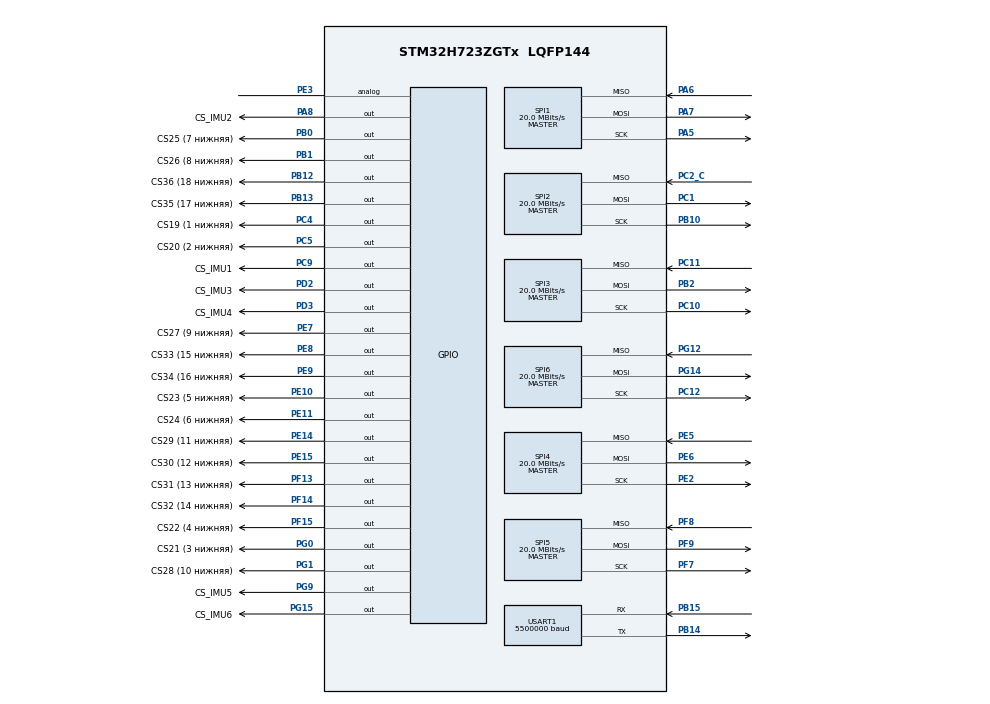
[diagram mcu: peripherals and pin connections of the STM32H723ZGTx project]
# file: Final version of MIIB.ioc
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Bdma.Request0=SPI6_RX
Bdma.Request1=SPI6_TX
Bdma.RequestsNb=2
Bdma.SPI6_RX.0.Direction=DMA_PERIPH_TO_MEMORY
Bdma.SPI6_RX.0.EventEnable=DISABLE
Bdma.SPI6_RX.0.Instance=BDMA_Channel0
Bdma.SPI6_RX.0.MemDataAlignment=DMA_MDATAALIGN_BYTE
Bdma.SPI6_RX.0.MemInc=DMA_MINC_ENABLE
Bdma.SPI6_RX.0.Mode=DMA_NORMAL
Bdma.SPI6_RX.0.PeriphDataAlignment=DMA_PDATAALIGN_BYTE
Bdma.SPI6_RX.0.PeriphInc=DMA_PINC_DISABLE
Bdma.SPI6_RX.0.Polarity=HAL_DMAMUX_REQ_GEN_RISING
Bdma.SPI6_RX.0.Priority=DMA_PRIORITY_VERY_HIGH
Bdma.SPI6_RX.0.RequestNumber=1
Bdma.SPI6_RX.0.SignalID=NONE
Bdma.SPI6_RX.0.SyncEnable=DISABLE
Bdma.SPI6_RX.0.SyncPolarity=HAL_DMAMUX_SYNC_NO_EVENT
Bdma.SPI6_RX.0.SyncRequestNumber=1
Bdma.SPI6_RX.0.SyncSignalID=NONE
Bdma.SPI6_TX.1.Direction=DMA_MEMORY_TO_PERIPH
Bdma.SPI6_TX.1.EventEnable=DISABLE
Bdma.SPI6_TX.1.Instance=BDMA_Channel1
Bdma.SPI6_TX.1.MemDataAlignment=DMA_MDATAALIGN_BYTE
Bdma.SPI6_TX.1.MemInc=DMA_MINC_ENABLE
Bdma.SPI6_TX.1.Mode=DMA_NORMAL
Bdma.SPI6_TX.1.PeriphDataAlignment=DMA_PDATAALIGN_BYTE
Bdma.SPI6_TX.1.PeriphInc=DMA_PINC_DISABLE
Bdma.SPI6_TX.1.Polarity=HAL_DMAMUX_REQ_GEN_RISING
Bdma.SPI6_TX.1.Priority=DMA_PRIORITY_HIGH
Bdma.SPI6_TX.1.RequestNumber=1
Bdma.SPI6_TX.1.SignalID=NONE
Bdma.SPI6_TX.1.SyncEnable=DISABLE
Bdma.SPI6_TX.1.SyncPolarity=HAL_DMAMUX_SYNC_NO_EVENT
Bdma.SPI6_TX.1.SyncRequestNumber=1
Bdma.SPI6_TX.1.SyncSignalID=NONE
CORTEX_M7.default_mode_Activation=1
Dma.Request0=USART1_RX
Dma.Request1=USART1_TX
Dma.Request10=SPI5_RX
Dma.Request11=SPI5_TX
Dma.Request2=SPI1_RX
Dma.Request3=SPI1_TX
Dma.Request4=SPI2_RX
Dma.Request5=SPI2_TX
Dma.Request6=SPI3_RX
Dma.Request7=SPI3_TX
Dma.Request8=SPI4_RX
Dma.Request9=SPI4_TX
Dma.SPI1_RX.2.Direction=DMA_PERIPH_TO_MEMORY
Dma.SPI1_RX.2.EventEnable=DISABLE
Dma.SPI1_RX.2.FIFOMode=DMA_FIFOMODE_DISABLE
Dma.SPI1_RX.2.Instance=DMA1_Stream2
Dma.SPI1_RX.2.MemDataAlignment=DMA_MDATAALIGN_BYTE
Dma.SPI1_RX.2.MemInc=DMA_MINC_ENABLE
Dma.SPI1_RX.2.Mode=DMA_NORMAL
Dma.SPI1_RX.2.PeriphDataAlignment=DMA_PDATAALIGN_BYTE
Dma.SPI1_RX.2.PeriphInc=DMA_PINC_DISABLE
Dma.SPI1_RX.2.Polarity=HAL_DMAMUX_REQ_GEN_RISING
Dma.SPI1_RX.2.Priority=DMA_PRIORITY_VERY_HIGH
Dma.SPI1_RX.2.RequestNumber=1
Dma.SPI1_RX.2.SignalID=NONE
Dma.SPI1_RX.2.SyncEnable=DISABLE
Dma.SPI1_RX.2.SyncPolarity=HAL_DMAMUX_SYNC_NO_EVENT
Dma.SPI1_RX.2.SyncRequestNumber=1
Dma.SPI1_RX.2.SyncSignalID=NONE
Dma.SPI1_TX.3.Direction=DMA_MEMORY_TO_PERIPH
Dma.SPI1_TX.3.EventEnable=DISABLE
Dma.SPI1_TX.3.FIFOMode=DMA_FIFOMODE_DISABLE
Dma.SPI1_TX.3.Instance=DMA1_Stream3
Dma.SPI1_TX.3.MemDataAlignment=DMA_MDATAALIGN_BYTE
Dma.SPI1_TX.3.MemInc=DMA_MINC_ENABLE
Dma.SPI1_TX.3.Mode=DMA_NORMAL
Dma.SPI1_TX.3.PeriphDataAlignment=DMA_PDATAALIGN_BYTE
Dma.SPI1_TX.3.PeriphInc=DMA_PINC_DISABLE
Dma.SPI1_TX.3.Polarity=HAL_DMAMUX_REQ_GEN_RISING
Dma.SPI1_TX.3.Priority=DMA_PRIORITY_HIGH
Dma.SPI1_TX.3.RequestNumber=1
Dma.SPI1_TX.3.SignalID=NONE
Dma.SPI1_TX.3.SyncEnable=DISABLE
Dma.SPI1_TX.3.SyncPolarity=HAL_DMAMUX_SYNC_NO_EVENT
Dma.SPI1_TX.3.SyncRequestNumber=1
Dma.SPI1_TX.3.SyncSignalID=NONE
Dma.SPI2_RX.4.Direction=DMA_PERIPH_TO_MEMORY
Dma.SPI2_RX.4.EventEnable=DISABLE
Dma.SPI2_RX.4.FIFOMode=DMA_FIFOMODE_DISABLE
Dma.SPI2_RX.4.Instance=DMA1_Stream4
Dma.SPI2_RX.4.MemDataAlignment=DMA_MDATAALIGN_BYTE
Dma.SPI2_RX.4.MemInc=DMA_MINC_ENABLE
Dma.SPI2_RX.4.Mode=DMA_NORMAL
Dma.SPI2_RX.4.PeriphDataAlignment=DMA_PDATAALIGN_BYTE
Dma.SPI2_RX.4.PeriphInc=DMA_PINC_DISABLE
Dma.SPI2_RX.4.Polarity=HAL_DMAMUX_REQ_GEN_RISING
Dma.SPI2_RX.4.Priority=DMA_PRIORITY_VERY_HIGH
Dma.SPI2_RX.4.RequestNumber=1
Dma.SPI2_RX.4.SignalID=NONE
Dma.SPI2_RX.4.SyncEnable=DISABLE
Dma.SPI2_RX.4.SyncPolarity=HAL_DMAMUX_SYNC_NO_EVENT
Dma.SPI2_RX.4.SyncRequestNumber=1
Dma.SPI2_RX.4.SyncSignalID=NONE
Dma.SPI2_TX.5.Direction=DMA_MEMORY_TO_PERIPH
Dma.SPI2_TX.5.EventEnable=DISABLE
Dma.SPI2_TX.5.FIFOMode=DMA_FIFOMODE_DISABLE
Dma.SPI2_TX.5.Instance=DMA1_Stream5
Dma.SPI2_TX.5.MemDataAlignment=DMA_MDATAALIGN_BYTE
Dma.SPI2_TX.5.MemInc=DMA_MINC_ENABLE
Dma.SPI2_TX.5.Mode=DMA_NORMAL
Dma.SPI2_TX.5.PeriphDataAlignment=DMA_PDATAALIGN_BYTE
Dma.SPI2_TX.5.PeriphInc=DMA_PINC_DISABLE
Dma.SPI2_TX.5.Polarity=HAL_DMAMUX_REQ_GEN_RISING
Dma.SPI2_TX.5.Priority=DMA_PRIORITY_HIGH
Dma.SPI2_TX.5.RequestNumber=1
Dma.SPI2_TX.5.SignalID=NONE
Dma.SPI2_TX.5.SyncEnable=DISABLE
Dma.SPI2_TX.5.SyncPolarity=HAL_DMAMUX_SYNC_NO_EVENT
Dma.SPI2_TX.5.SyncRequestNumber=1
Dma.SPI2_TX.5.SyncSignalID=NONE
Dma.SPI3_RX.6.Direction=DMA_PERIPH_TO_MEMORY
Dma.SPI3_RX.6.EventEnable=DISABLE
Dma.SPI3_RX.6.FIFOMode=DMA_FIFOMODE_DISABLE
Dma.SPI3_RX.6.Instance=DMA1_Stream6
Dma.SPI3_RX.6.MemDataAlignment=DMA_MDATAALIGN_BYTE
Dma.SPI3_RX.6.MemInc=DMA_MINC_ENABLE
Dma.SPI3_RX.6.Mode=DMA_NORMAL
Dma.SPI3_RX.6.PeriphDataAlignment=DMA_PDATAALIGN_BYTE
Dma.SPI3_RX.6.PeriphInc=DMA_PINC_DISABLE
Dma.SPI3_RX.6.Polarity=HAL_DMAMUX_REQ_GEN_RISING
Dma.SPI3_RX.6.Priority=DMA_PRIORITY_VERY_HIGH
Dma.SPI3_RX.6.RequestNumber=1
Dma.SPI3_RX.6.SignalID=NONE
Dma.SPI3_RX.6.SyncEnable=DISABLE
Dma.SPI3_RX.6.SyncPolarity=HAL_DMAMUX_SYNC_NO_EVENT
Dma.SPI3_RX.6.SyncRequestNumber=1
Dma.SPI3_RX.6.SyncSignalID=NONE
Dma.SPI3_TX.7.Direction=DMA_MEMORY_TO_PERIPH
Dma.SPI3_TX.7.EventEnable=DISABLE
Dma.SPI3_TX.7.FIFOMode=DMA_FIFOMODE_DISABLE
Dma.SPI3_TX.7.Instance=DMA1_Stream7
Dma.SPI3_TX.7.MemDataAlignment=DMA_MDATAALIGN_BYTE
Dma.SPI3_TX.7.MemInc=DMA_MINC_ENABLE
Dma.SPI3_TX.7.Mode=DMA_NORMAL
Dma.SPI3_TX.7.PeriphDataAlignment=DMA_PDATAALIGN_BYTE
Dma.SPI3_TX.7.PeriphInc=DMA_PINC_DISABLE
Dma.SPI3_TX.7.Polarity=HAL_DMAMUX_REQ_GEN_RISING
Dma.SPI3_TX.7.Priority=DMA_PRIORITY_HIGH
Dma.SPI3_TX.7.RequestNumber=1
Dma.SPI3_TX.7.SignalID=NONE
Dma.SPI3_TX.7.SyncEnable=DISABLE
Dma.SPI3_TX.7.SyncPolarity=HAL_DMAMUX_SYNC_NO_EVENT
Dma.SPI3_TX.7.SyncRequestNumber=1
Dma.SPI3_TX.7.SyncSignalID=NONE
Dma.SPI4_RX.8.Direction=DMA_PERIPH_TO_MEMORY
Dma.SPI4_RX.8.EventEnable=DISABLE
Dma.SPI4_RX.8.FIFOMode=DMA_FIFOMODE_DISABLE
Dma.SPI4_RX.8.Instance=DMA2_Stream0
Dma.SPI4_RX.8.MemDataAlignment=DMA_MDATAALIGN_BYTE
Dma.SPI4_RX.8.MemInc=DMA_MINC_ENABLE
Dma.SPI4_RX.8.Mode=DMA_NORMAL
Dma.SPI4_RX.8.PeriphDataAlignment=DMA_PDATAALIGN_BYTE
Dma.SPI4_RX.8.PeriphInc=DMA_PINC_DISABLE
Dma.SPI4_RX.8.Polarity=HAL_DMAMUX_REQ_GEN_RISING
Dma.SPI4_RX.8.Priority=DMA_PRIORITY_VERY_HIGH
Dma.SPI4_RX.8.RequestNumber=1
Dma.SPI4_RX.8.SignalID=NONE
Dma.SPI4_RX.8.SyncEnable=DISABLE
Dma.SPI4_RX.8.SyncPolarity=HAL_DMAMUX_SYNC_NO_EVENT
Dma.SPI4_RX.8.SyncRequestNumber=1
Dma.SPI4_RX.8.SyncSignalID=NONE
Dma.SPI4_TX.9.Direction=DMA_MEMORY_TO_PERIPH
Dma.SPI4_TX.9.EventEnable=DISABLE
Dma.SPI4_TX.9.FIFOMode=DMA_FIFOMODE_DISABLE
Dma.SPI4_TX.9.Instance=DMA2_Stream1
Dma.SPI4_TX.9.MemDataAlignment=DMA_MDATAALIGN_BYTE
Dma.SPI4_TX.9.MemInc=DMA_MINC_ENABLE
Dma.SPI4_TX.9.Mode=DMA_NORMAL
Dma.SPI4_TX.9.PeriphDataAlignment=DMA_PDATAALIGN_BYTE
Dma.SPI4_TX.9.PeriphInc=DMA_PINC_DISABLE
Dma.SPI4_TX.9.Polarity=HAL_DMAMUX_REQ_GEN_RISING
Dma.SPI4_TX.9.Priority=DMA_PRIORITY_HIGH
Dma.SPI4_TX.9.RequestNumber=1
Dma.SPI4_TX.9.SignalID=NONE
Dma.SPI4_TX.9.SyncEnable=DISABLE
Dma.SPI4_TX.9.SyncPolarity=HAL_DMAMUX_SYNC_NO_EVENT
Dma.SPI4_TX.9.SyncRequestNumber=1
Dma.SPI4_TX.9.SyncSignalID=NONE
Dma.SPI5_RX.10.Direction=DMA_PERIPH_TO_MEMORY
Dma.SPI5_RX.10.EventEnable=DISABLE
Dma.SPI5_RX.10.FIFOMode=DMA_FIFOMODE_DISABLE
Dma.SPI5_RX.10.Instance=DMA2_Stream2
Dma.SPI5_RX.10.MemDataAlignment=DMA_MDATAALIGN_BYTE
Dma.SPI5_RX.10.MemInc=DMA_MINC_ENABLE
Dma.SPI5_RX.10.Mode=DMA_NORMAL
Dma.SPI5_RX.10.PeriphDataAlignment=DMA_PDATAALIGN_BYTE
Dma.SPI5_RX.10.PeriphInc=DMA_PINC_DISABLE
Dma.SPI5_RX.10.Polarity=HAL_DMAMUX_REQ_GEN_RISING
Dma.SPI5_RX.10.Priority=DMA_PRIORITY_VERY_HIGH
Dma.SPI5_RX.10.RequestNumber=1
Dma.SPI5_RX.10.SignalID=NONE
Dma.SPI5_RX.10.SyncEnable=DISABLE
Dma.SPI5_RX.10.SyncPolarity=HAL_DMAMUX_SYNC_NO_EVENT
Dma.SPI5_RX.10.SyncRequestNumber=1
Dma.SPI5_RX.10.SyncSignalID=NONE
Dma.SPI5_TX.11.Direction=DMA_MEMORY_TO_PERIPH
Dma.SPI5_TX.11.EventEnable=DISABLE
Dma.SPI5_TX.11.FIFOMode=DMA_FIFOMODE_DISABLE
Dma.SPI5_TX.11.Instance=DMA2_Stream3
Dma.SPI5_TX.11.MemDataAlignment=DMA_MDATAALIGN_BYTE
Dma.SPI5_TX.11.MemInc=DMA_MINC_ENABLE
Dma.SPI5_TX.11.Mode=DMA_NORMAL
Dma.SPI5_TX.11.PeriphDataAlignment=DMA_PDATAALIGN_BYTE
Dma.SPI5_TX.11.PeriphInc=DMA_PINC_DISABLE
Dma.SPI5_TX.11.Polarity=HAL_DMAMUX_REQ_GEN_RISING
Dma.SPI5_TX.11.Priority=DMA_PRIORITY_HIGH
Dma.SPI5_TX.11.RequestNumber=1
Dma.SPI5_TX.11.SignalID=NONE
Dma.SPI5_TX.11.SyncEnable=DISABLE
Dma.SPI5_TX.11.SyncPolarity=HAL_DMAMUX_SYNC_NO_EVENT
Dma.SPI5_TX.11.SyncRequestNumber=1
Dma.SPI5_TX.11.SyncSignalID=NONE
Dma.USART1_RX.0.Direction=DMA_PERIPH_TO_MEMORY
Dma.USART1_RX.0.EventEnable=DISABLE
Dma.USART1_RX.0.FIFOMode=DMA_FIFOMODE_DISABLE
Dma.USART1_RX.0.Instance=DMA1_Stream0
Dma.USART1_RX.0.MemDataAlignment=DMA_MDATAALIGN_BYTE
Dma.USART1_RX.0.MemInc=DMA_MINC_ENABLE
Dma.USART1_RX.0.Mode=DMA_NORMAL
Dma.USART1_RX.0.PeriphDataAlignment=DMA_PDATAALIGN_BYTE
Dma.USART1_RX.0.PeriphInc=DMA_PINC_DISABLE
Dma.USART1_RX.0.Polarity=HAL_DMAMUX_REQ_GEN_RISING
Dma.USART1_RX.0.Priority=DMA_PRIORITY_HIGH
Dma.USART1_RX.0.RequestNumber=1
Dma.USART1_RX.0.SignalID=NONE
Dma.USART1_RX.0.SyncEnable=DISABLE
Dma.USART1_RX.0.SyncPolarity=HAL_DMAMUX_SYNC_NO_EVENT
Dma.USART1_RX.0.SyncRequestNumber=1
Dma.USART1_RX.0.SyncSignalID=NONE
Dma.USART1_TX.1.Direction=DMA_MEMORY_TO_PERIPH
Dma.USART1_TX.1.EventEnable=DISABLE
Dma.USART1_TX.1.FIFOMode=DMA_FIFOMODE_DISABLE
Dma.USART1_TX.1.Instance=DMA1_Stream1
Dma.USART1_TX.1.MemDataAlignment=DMA_MDATAALIGN_BYTE
Dma.USART1_TX.1.MemInc=DMA_MINC_ENABLE
Dma.USART1_TX.1.Mode=DMA_NORMAL
Dma.USART1_TX.1.PeriphDataAlignment=DMA_PDATAALIGN_BYTE
Dma.USART1_TX.1.PeriphInc=DMA_PINC_DISABLE
Dma.USART1_TX.1.Polarity=HAL_DMAMUX_REQ_GEN_RISING
Dma.USART1_TX.1.Priority=DMA_PRIORITY_MEDIUM
Dma.USART1_TX.1.RequestNumber=1
Dma.USART1_TX.1.SignalID=NONE
Dma.USART1_TX.1.SyncEnable=DISABLE
Dma.USART1_TX.1.SyncPolarity=HAL_DMAMUX_SYNC_NO_EVENT
Dma.USART1_TX.1.SyncRequestNumber=1
Dma.USART1_TX.1.SyncSignalID=NONE
Mcu.Family=STM32H7
Mcu.Name=STM32H723ZGTx
Mcu.Package=LQFP144
NVIC.BDMA_Channel0_IRQn=true\:0\:0\:false\:false\:true\:false\:true\:true
NVIC.BDMA_Channel1_IRQn=true\:0\:0\:false\:false\:true\:false\:true\:true
NVIC.DMA1_Stream0_IRQn=true\:0\:0\:false\:false\:true\:false\:true\:true
NVIC.DMA1_Stream1_IRQn=true\:0\:0\:false\:false\:true\:false\:true\:true
NVIC.DMA1_Stream2_IRQn=true\:0\:0\:false\:false\:true\:false\:true\:true
NVIC.DMA1_Stream3_IRQn=true\:0\:0\:false\:false\:true\:false\:true\:true
NVIC.DMA1_Stream4_IRQn=true\:0\:0\:false\:false\:true\:false\:true\:true
NVIC.DMA1_Stream5_IRQn=true\:0\:0\:false\:false\:true\:false\:true\:true
NVIC.DMA1_Stream6_IRQn=true\:0\:0\:false\:false\:true\:false\:true\:true
NVIC.DMA1_Stream7_IRQn=true\:0\:0\:false\:false\:true\:false\:true\:true
NVIC.DMA2_Stream0_IRQn=true\:0\:0\:false\:false\:true\:false\:true\:true
NVIC.DMA2_Stream1_IRQn=true\:0\:0\:false\:false\:true\:false\:true\:true
NVIC.DMA2_Stream2_IRQn=true\:0\:0\:false\:false\:true\:false\:true\:true
NVIC.DMA2_Stream3_IRQn=true\:0\:0\:false\:false\:true\:false\:true\:true
NVIC.PriorityGroup=NVIC_PRIORITYGROUP_4
NVIC.SPI1_IRQn=true\:0\:0\:false\:false\:true\:false\:true\:true
NVIC.SPI2_IRQn=true\:0\:0\:false\:false\:true\:false\:true\:true
NVIC.SPI3_IRQn=true\:0\:0\:false\:false\:true\:false\:true\:true
NVIC.SPI4_IRQn=true\:0\:0\:false\:false\:true\:false\:true\:true
NVIC.SPI5_IRQn=true\:0\:0\:false\:false\:true\:false\:true\:true
NVIC.SPI6_IRQn=true\:0\:0\:false\:false\:true\:false\:true\:true
NVIC.TIM6_DAC_IRQn=true\:0\:0\:true\:false\:true\:true\:true\:true
PA13(JTMS/SWDIO).Mode=Serial_Wire
PA13(JTMS/SWDIO).Signal=DEBUG_JTMS-SWDIO
PA14(JTCK/SWCLK).Mode=Serial_Wire
PA14(JTCK/SWCLK).Signal=DEBUG_JTCK-SWCLK
PA5.GPIO_Speed=GPIO_SPEED_FREQ_VERY_HIGH
PA5.Mode=Full_Duplex_Master
PA5.Signal=SPI1_SCK
PA6.GPIO_Speed=GPIO_SPEED_FREQ_VERY_HIGH
PA6.Mode=Full_Duplex_Master
PA6.Signal=SPI1_MISO
PA7.GPIO_Speed=GPIO_SPEED_FREQ_VERY_HIGH
PA7.Mode=Full_Duplex_Master
PA7.Signal=SPI1_MOSI
PA8.GPIO_Label=CS_IMU2
PA8.GPIO_Speed=GPIO_SPEED_FREQ_VERY_HIGH
PA8.PinState=GPIO_PIN_SET
PA8.Signal=GPIO_Output
PB0.GPIO_Label=CS25 (7 \u043D\u0438\u0436\u043D\u044F\u044F)
PB0.GPIO_Speed=GPIO_SPEED_FREQ_HIGH
PB0.Signal=GPIO_Output
PB1.GPIO_Label=CS26 (8 \u043D\u0438\u0436\u043D\u044F\u044F)
PB1.GPIO_Speed=GPIO_SPEED_FREQ_HIGH
PB1.Signal=GPIO_Output
PB10.GPIO_Speed=GPIO_SPEED_FREQ_VERY_HIGH
PB10.Mode=Full_Duplex_Master
PB10.Signal=SPI2_SCK
PB12.GPIO_Label=CS36 (18 \u043D\u0438\u0436\u043D\u044F\u044F)
PB12.GPIO_Speed=GPIO_SPEED_FREQ_HIGH
PB12.Signal=GPIO_Output
PB13.GPIO_Label=CS35 (17 \u043D\u0438\u0436\u043D\u044F\u044F)
PB13.GPIO_Speed=GPIO_SPEED_FREQ_HIGH
PB13.Signal=GPIO_Output
PB14.GPIO_Speed=GPIO_SPEED_FREQ_VERY_HIGH
PB14.Mode=Asynchronous
PB14.Signal=USART1_TX
PB15.GPIO_Speed=GPIO_SPEED_FREQ_VERY_HIGH
PB15.Mode=Asynchronous
PB15.Signal=USART1_RX
PB2.GPIO_Speed=GPIO_SPEED_FREQ_VERY_HIGH
PB2.Mode=Full_Duplex_Master
PB2.Signal=SPI3_MOSI
PC1.GPIO_Speed=GPIO_SPEED_FREQ_VERY_HIGH
PC1.Mode=Full_Duplex_Master
PC1.Signal=SPI2_MOSI
PC10.GPIO_Speed=GPIO_SPEED_FREQ_VERY_HIGH
PC10.Mode=Full_Duplex_Master
PC10.Signal=SPI3_SCK
PC11.GPIO_Speed=GPIO_SPEED_FREQ_VERY_HIGH
PC11.Mode=Full_Duplex_Master
PC11.Signal=SPI3_MISO
PC12.GPIO_Speed=GPIO_SPEED_FREQ_VERY_HIGH
PC12.Mode=Full_Duplex_Master
PC12.Signal=SPI6_SCK
PC2_C.GPIO_Speed=GPIO_SPEED_FREQ_VERY_HIGH
PC2_C.Mode=Full_Duplex_Master
PC2_C.Signal=SPI2_MISO
PC4.GPIO_Label=CS19 (1 \u043D\u0438\u0436\u043D\u044F\u044F)
PC4.GPIO_Speed=GPIO_SPEED_FREQ_HIGH
PC4.Signal=GPIO_Output
PC5.GPIO_Label=CS20 (2 \u043D\u0438\u0436\u043D\u044F\u044F)
PC5.GPIO_Speed=GPIO_SPEED_FREQ_HIGH
PC5.Signal=GPIO_Output
PC9.GPIO_Label=CS_IMU1
PC9.GPIO_Speed=GPIO_SPEED_FREQ_VERY_HIGH
PC9.PinState=GPIO_PIN_SET
PC9.Signal=GPIO_Output
PD2.GPIO_Label=CS_IMU3
PD2.GPIO_Speed=GPIO_SPEED_FREQ_VERY_HIGH
PD2.PinState=GPIO_PIN_SET
PD2.Signal=GPIO_Output
PD3.GPIO_Label=CS_IMU4
PD3.GPIO_Speed=GPIO_SPEED_FREQ_VERY_HIGH
PD3.PinState=GPIO_PIN_SET
PD3.Signal=GPIO_Output
PE10.GPIO_Label=CS23 (5 \u043D\u0438\u0436\u043D\u044F\u044F)
PE10.GPIO_Speed=GPIO_SPEED_FREQ_HIGH
PE10.Signal=GPIO_Output
PE11.GPIO_Label=CS24 (6 \u043D\u0438\u0436\u043D\u044F\u044F)
PE11.GPIO_Speed=GPIO_SPEED_FREQ_HIGH
PE11.Signal=GPIO_Output
PE14.GPIO_Label=CS29 (11 \u043D\u0438\u0436\u043D\u044F\u044F)
PE14.GPIO_Speed=GPIO_SPEED_FREQ_HIGH
PE14.Signal=GPIO_Output
PE15.GPIO_Label=CS30 (12 \u043D\u0438\u0436\u043D\u044F\u044F)
PE15.GPIO_Speed=GPIO_SPEED_FREQ_HIGH
PE15.Signal=GPIO_Output
PE2.GPIO_Speed=GPIO_SPEED_FREQ_VERY_HIGH
PE2.Mode=Full_Duplex_Master
PE2.Signal=SPI4_SCK
PE3.Signal=GPIO_Analog
PE5.GPIO_Speed=GPIO_SPEED_FREQ_VERY_HIGH
PE5.Mode=Full_Duplex_Master
PE5.Signal=SPI4_MISO
PE6.GPIO_Speed=GPIO_SPEED_FREQ_VERY_HIGH
PE6.Mode=Full_Duplex_Master
PE6.Signal=SPI4_MOSI
PE7.GPIO_Label=CS27 (9 \u043D\u0438\u0436\u043D\u044F\u044F)
PE7.GPIO_Speed=GPIO_SPEED_FREQ_HIGH
PE7.Signal=GPIO_Output
PE8.GPIO_Label=CS33 (15 \u043D\u0438\u0436\u043D\u044F\u044F)
PE8.GPIO_Speed=GPIO_SPEED_FREQ_HIGH
PE8.Signal=GPIO_Output
PE9.GPIO_Label=CS34 (16 \u043D\u0438\u0436\u043D\u044F\u044F)
PE9.GPIO_Speed=GPIO_SPEED_FREQ_HIGH
PE9.Signal=GPIO_Output
PF13.GPIO_Label=CS31 (13 \u043D\u0438\u0436\u043D\u044F\u044F)
PF13.GPIO_Speed=GPIO_SPEED_FREQ_HIGH
PF13.Signal=GPIO_Output
PF14.GPIO_Label=CS32 (14 \u043D\u0438\u0436\u043D\u044F\u044F)
PF14.GPIO_Speed=GPIO_SPEED_FREQ_HIGH
PF14.Signal=GPIO_Output
PF15.GPIO_Label=CS22 (4 \u043D\u0438\u0436\u043D\u044F\u044F)
PF15.GPIO_Speed=GPIO_SPEED_FREQ_HIGH
PF15.Signal=GPIO_Output
PF7.GPIO_Speed=GPIO_SPEED_FREQ_VERY_HIGH
PF7.Mode=Full_Duplex_Master
PF7.Signal=SPI5_SCK
PF8.GPIO_Speed=GPIO_SPEED_FREQ_VERY_HIGH
PF8.Mode=Full_Duplex_Master
PF8.Signal=SPI5_MISO
PF9.GPIO_Speed=GPIO_SPEED_FREQ_VERY_HIGH
PF9.Mode=Full_Duplex_Master
PF9.Signal=SPI5_MOSI
PG0.GPIO_Label=CS21 (3 \u043D\u0438\u0436\u043D\u044F\u044F)
PG0.GPIO_Speed=GPIO_SPEED_FREQ_HIGH
PG0.Signal=GPIO_Output
PG1.GPIO_Label=CS28 (10 \u043D\u0438\u0436\u043D\u044F\u044F)
PG1.GPIO_Speed=GPIO_SPEED_FREQ_HIGH
PG1.Signal=GPIO_Output
PG12.GPIO_Speed=GPIO_SPEED_FREQ_VERY_HIGH
PG12.Mode=Full_Duplex_Master
PG12.Signal=SPI6_MISO
PG14.GPIO_Speed=GPIO_SPEED_FREQ_VERY_HIGH
PG14.Mode=Full_Duplex_Master
PG14.Signal=SPI6_MOSI
PG15.GPIO_Label=CS_IMU6
PG15.GPIO_Speed=GPIO_SPEED_FREQ_VERY_HIGH
PG15.PinState=GPIO_PIN_SET
PG15.Signal=GPIO_Output
PG9.GPIO_Label=CS_IMU5
PG9.GPIO_Speed=GPIO_SPEED_FREQ_VERY_HIGH
PG9.PinState=GPIO_PIN_SET
PG9.Signal=GPIO_Output
PH0-OSC_IN.Mode=HSE-External-Oscillator
PH0-OSC_IN.Signal=RCC_OSC_IN
PH1-OSC_OUT.Mode=HSE-External-Oscillator
PH1-OSC_OUT.Signal=RCC_OSC_OUT
ProjectManager.HeapSize=0x200
ProjectManager.StackSize=0x400
ProjectManager.TargetToolchain=STM32CubeIDE
RCC.ADCFreq_Value=40000000
RCC.APB1Freq_Value=137500000
RCC.APB2Freq_Value=137500000
RCC.APB3Freq_Value=137500000
RCC.APB4Freq_Value=137500000
RCC.CortexFreq_Value=550000000
RCC.D1PPRE=RCC_APB3_DIV2
RCC.D2PPRE1=RCC_APB1_DIV2
RCC.D2PPRE2=RCC_APB2_DIV2
RCC.D3PPRE=RCC_APB4_DIV2
RCC.DIVM1=1
RCC.DIVM2=1
RCC.DIVM3=2
RCC.DIVN1=34
RCC.DIVN2=12
RCC.DIVN3=48
RCC.DIVP1=1
RCC.DIVP2=5
RCC.DIVQ2=5
RCC.HCLKFreq_Value=275000000
RCC.HPRE=RCC_HCLK_DIV2
RCC.HSE_VALUE=16000000
RCC.PLL2FRACN=4096
RCC.PLLFRACN=3072
RCC.PLLSourceVirtual=RCC_PLLSOURCE_HSE
RCC.SPI123CLockSelection=RCC_SPI123CLKSOURCE_PLL2
RCC.SPI6CLockSelection=RCC_SPI6CLKSOURCE_PLL2
RCC.SYSCLKFreq_VALUE=550000000
RCC.SYSCLKSource=RCC_SYSCLKSOURCE_PLLCLK
RCC.Spi45ClockSelection=RCC_SPI45CLKSOURCE_PLL2
RCC.USBFreq_Value=275000000
SPI1.BaudRatePrescaler=SPI_BAUDRATEPRESCALER_2
SPI1.CLKPhase=SPI_PHASE_2EDGE
SPI1.CalculateBaudRate=20.0 MBits/s
SPI1.DataSize=SPI_DATASIZE_8BIT
SPI1.Direction=SPI_DIRECTION_2LINES
SPI1.Mode=SPI_MODE_MASTER
SPI1.NSSPMode=SPI_NSS_PULSE_DISABLE
SPI1.VirtualType=VM_MASTER
SPI2.CLKPhase=SPI_PHASE_2EDGE
SPI2.CalculateBaudRate=20.0 MBits/s
SPI2.DataSize=SPI_DATASIZE_8BIT
SPI2.Direction=SPI_DIRECTION_2LINES
SPI2.Mode=SPI_MODE_MASTER
SPI2.NSSPMode=SPI_NSS_PULSE_DISABLE
SPI2.VirtualType=VM_MASTER
SPI3.CLKPhase=SPI_PHASE_2EDGE
SPI3.CalculateBaudRate=20.0 MBits/s
SPI3.DataSize=SPI_DATASIZE_8BIT
SPI3.Direction=SPI_DIRECTION_2LINES
SPI3.Mode=SPI_MODE_MASTER
SPI3.NSSPMode=SPI_NSS_PULSE_DISABLE
SPI3.VirtualType=VM_MASTER
SPI4.CLKPhase=SPI_PHASE_2EDGE
SPI4.CalculateBaudRate=20.0 MBits/s
SPI4.DataSize=SPI_DATASIZE_8BIT
SPI4.Direction=SPI_DIRECTION_2LINES
SPI4.Mode=SPI_MODE_MASTER
SPI4.NSSPMode=SPI_NSS_PULSE_DISABLE
SPI4.VirtualType=VM_MASTER
SPI5.CLKPhase=SPI_PHASE_2EDGE
SPI5.CalculateBaudRate=20.0 MBits/s
SPI5.DataSize=SPI_DATASIZE_8BIT
SPI5.Direction=SPI_DIRECTION_2LINES
SPI5.Mode=SPI_MODE_MASTER
SPI5.NSSPMode=SPI_NSS_PULSE_DISABLE
SPI5.VirtualType=VM_MASTER
SPI6.BaudRatePrescaler=SPI_BAUDRATEPRESCALER_2
SPI6.CLKPhase=SPI_PHASE_2EDGE
SPI6.CLKPolarity=SPI_POLARITY_LOW
SPI6.CalculateBaudRate=20.0 MBits/s
SPI6.DataSize=SPI_DATASIZE_8BIT
SPI6.Direction=SPI_DIRECTION_2LINES
SPI6.Mode=SPI_MODE_MASTER
SPI6.NSSPMode=SPI_NSS_PULSE_DISABLE
SPI6.VirtualType=VM_MASTER
TIM6.Period=2499
TIM6.Prescaler=274
USART1.BaudRate=5500000
USART1.OverSampling=UART_OVERSAMPLING_8
USART1.VirtualMode-Asynchronous=VM_ASYNC
VP_MEMORYMAP_VS_MEMORYMAP.Mode=CurAppReg
VP_TIM6_VS_ClockSourceINT.Mode=Enable_Timer
VP_TIM7_VS_ClockSourceINT.Mode=Enable_Timer
board=custom

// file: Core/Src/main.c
/* USER CODE BEGIN Header */
/*
 * Copyright (c) 2026 STMicroelectronics.
 * All rights reserved.
 *
 * This software is licensed under terms that can be found in the LICENSE file
 * in the root directory of this software component.
 * If no LICENSE file comes with this software, it is provided AS-IS.
 */
/* USER CODE END Header */

#include "main.h"

/* USER CODE BEGIN Includes */
#include "icm45686_spi.h"
#include "icm45686_data.h"
#include "uart_telemetry.h"
/* USER CODE END Includes */

void SystemClock_Config(void);
void PeriphCommonClock_Config(void);

static void MPU_Config(void);
static void MX_GPIO_Init(void);
static void MX_DMA_Init(void);
static void MX_BDMA_Init(void);
static void MX_USART1_UART_Init(void);
static void MX_TIM6_Init(void);
static void MX_TIM7_Init(void);
static void MX_SPI1_Init(void);
static void MX_SPI2_Init(void);
static void MX_SPI3_Init(void);
static void MX_SPI4_Init(void);
static void MX_SPI5_Init(void);
static void MX_SPI6_Init(void);

int main(void)
{

  MPU_Config();

  LL_APB4_GRP1_EnableClock(LL_APB4_GRP1_PERIPH_SYSCFG);

  NVIC_SetPriorityGrouping(NVIC_PRIORITYGROUP_4);

  NVIC_SetPriority(
      SysTick_IRQn,
      NVIC_EncodePriority(NVIC_GetPriorityGrouping(), 15, 0));

  SystemClock_Config();
  PeriphCommonClock_Config();

  MX_GPIO_Init();

  MX_DMA_Init();
  MX_BDMA_Init();

  MX_SPI1_Init();
  MX_SPI5_Init();
  MX_SPI4_Init();

  MX_SPI2_Init();
  MX_SPI3_Init();
  MX_SPI6_Init();

  MX_TIM6_Init();
  MX_TIM7_Init();

  MX_USART1_UART_Init();

  /* USER CODE BEGIN 2 */

  ICM_BusesInit();

  uint64_t imu_faults = ICM_InitAllSensors();
  (void)imu_faults;

  UART_Telemetry_Init();

  /*
   * TIM7 watchdog: 1 кГц.
   * NVIC preemption priority 3, ниже SPI/DMA/TIM6.
   */
  LL_TIM_SetCounter(TIM7, 0U);
  LL_TIM_ClearFlag_UPDATE(TIM7);
  LL_TIM_EnableIT_UPDATE(TIM7);
  LL_TIM_EnableCounter(TIM7);

  /*
   * TIM6: 2.5 мс, восемь FIFO-пакетов @ 3200 Гц,
   * один output frame @ 400 Гц.
   */
  LL_TIM_SetCounter(TIM6, 0U);
  LL_TIM_ClearFlag_UPDATE(TIM6);
  LL_TIM_EnableIT_UPDATE(TIM6);
  LL_TIM_EnableCounter(TIM6);

  /* USER CODE END 2 */

  /* USER CODE BEGIN WHILE */
  while (1)
  {
    uint32_t events = ICM_ConsumeEvents();

    /*
     * Pipeline выполняется только в main loop:
     * raw FIFO parsing -> averaging -> один RS-кадр.
     */
    if ((events & ICM_EVT_BATCH_READY) != 0U)
    {
      ICM_ParseAllFIFO();
      ICM_AverageAllBatches();
      UART_BuildAndSendSyncFrame();
    }

    /*
     * Recovery выполняется существующей FSM.
     * Здесь не запускается блокирующий register/FIFO I/O.
     */
    if ((events & (ICM_EVT_BUS0_FAULT |
                   ICM_EVT_BUS1_FAULT |
                   ICM_EVT_BUS2_FAULT)) != 0U)
    {
    }

    if ((events & ICM_EVT_DMA_TIMEOUT) != 0U)
    {
    }

    /* USER CODE END WHILE */

  }
}

void SystemClock_Config(void)
{
  LL_FLASH_SetLatency(LL_FLASH_LATENCY_4);

  while (LL_FLASH_GetLatency() != LL_FLASH_LATENCY_4)
  {
  }

  LL_PWR_ConfigSupply(LL_PWR_LDO_SUPPLY);
  LL_PWR_SetRegulVoltageScaling(LL_PWR_REGU_VOLTAGE_SCALE0);

  while (LL_PWR_IsActiveFlag_VOS() == 0)
  {
  }

  LL_RCC_HSE_Enable();

  while (LL_RCC_HSE_IsReady() != 1)
  {
  }

  LL_RCC_PLL_SetSource(LL_RCC_PLLSOURCE_HSE);

  LL_RCC_PLL1P_Enable();
  LL_RCC_PLL1R_Enable();

  LL_RCC_PLL1_SetVCOInputRange(LL_RCC_PLLINPUTRANGE_8_16);
  LL_RCC_PLL1_SetVCOOutputRange(LL_RCC_PLLVCORANGE_WIDE);

  LL_RCC_PLL1_SetM(1);
  LL_RCC_PLL1_SetN(34);
  LL_RCC_PLL1_SetP(1);
  LL_RCC_PLL1_SetQ(2);
  LL_RCC_PLL1_SetR(2);

  LL_RCC_PLL1_SetFRACN(3072);
  LL_RCC_PLL1FRACN_Enable();

  LL_RCC_PLL1_Enable();

  while (LL_RCC_PLL1_IsReady() != 1)
  {
  }

  LL_RCC_SetAHBPrescaler(LL_RCC_AHB_DIV_2);
  LL_RCC_SetSysClkSource(LL_RCC_SYS_CLKSOURCE_PLL1);

  while (LL_RCC_GetSysClkSource() != LL_RCC_SYS_CLKSOURCE_STATUS_PLL1)
  {
  }

  LL_RCC_SetSysPrescaler(LL_RCC_SYSCLK_DIV_1);
  LL_RCC_SetAHBPrescaler(LL_RCC_AHB_DIV_2);

  LL_RCC_SetAPB1Prescaler(LL_RCC_APB1_DIV_2);
  LL_RCC_SetAPB2Prescaler(LL_RCC_APB2_DIV_2);
  LL_RCC_SetAPB3Prescaler(LL_RCC_APB3_DIV_2);
  LL_RCC_SetAPB4Prescaler(LL_RCC_APB4_DIV_2);

  LL_Init1msTick(550000000);
  LL_SetSystemCoreClock(550000000);
}

void PeriphCommonClock_Config(void)
{
  LL_RCC_PLL2P_Enable();
  LL_RCC_PLL2Q_Enable();

  LL_RCC_PLL2_SetVCOInputRange(LL_RCC_PLLINPUTRANGE_8_16);
  LL_RCC_PLL2_SetVCOOutputRange(LL_RCC_PLLVCORANGE_WIDE);

  LL_RCC_PLL2_SetM(1);
  LL_RCC_PLL2_SetN(12);
  LL_RCC_PLL2_SetP(5);
  LL_RCC_PLL2_SetQ(5);
  LL_RCC_PLL2_SetR(2);

  LL_RCC_PLL2_SetFRACN(4096);
  LL_RCC_PLL2FRACN_Enable();

  LL_RCC_PLL2_Enable();

  while (LL_RCC_PLL2_IsReady() != 1)
  {
  }
}

static void MX_SPI1_Init(void)
{

  LL_SPI_InitTypeDef SPI_InitStruct = {0};
  LL_GPIO_InitTypeDef GPIO_InitStruct = {0};

  LL_RCC_SetSPIClockSource(LL_RCC_SPI123_CLKSOURCE_PLL2P);

  LL_APB2_GRP1_EnableClock(LL_APB2_GRP1_PERIPH_SPI1);
  LL_AHB4_GRP1_EnableClock(LL_AHB4_GRP1_PERIPH_GPIOA);

  GPIO_InitStruct.Pin =
      LL_GPIO_PIN_5 | LL_GPIO_PIN_6 | LL_GPIO_PIN_7;

  GPIO_InitStruct.Mode = LL_GPIO_MODE_ALTERNATE;
  GPIO_InitStruct.Speed = LL_GPIO_SPEED_FREQ_VERY_HIGH;
  GPIO_InitStruct.OutputType = LL_GPIO_OUTPUT_PUSHPULL;
  GPIO_InitStruct.Pull = LL_GPIO_PULL_NO;
  GPIO_InitStruct.Alternate = LL_GPIO_AF_5;

  LL_GPIO_Init(GPIOA, &GPIO_InitStruct);

  LL_DMA_SetPeriphRequest(
      DMA1, LL_DMA_STREAM_2, LL_DMAMUX1_REQ_SPI1_RX);

  LL_DMA_SetDataTransferDirection(
      DMA1, LL_DMA_STREAM_2, LL_DMA_DIRECTION_PERIPH_TO_MEMORY);

  LL_DMA_SetStreamPriorityLevel(
      DMA1, LL_DMA_STREAM_2, LL_DMA_PRIORITY_VERYHIGH);

  LL_DMA_SetMode(DMA1, LL_DMA_STREAM_2, LL_DMA_MODE_NORMAL);

  LL_DMA_SetPeriphIncMode(
      DMA1, LL_DMA_STREAM_2, LL_DMA_PERIPH_NOINCREMENT);

  LL_DMA_SetMemoryIncMode(
      DMA1, LL_DMA_STREAM_2, LL_DMA_MEMORY_INCREMENT);

  LL_DMA_SetPeriphSize(
      DMA1, LL_DMA_STREAM_2, LL_DMA_PDATAALIGN_BYTE);

  LL_DMA_SetMemorySize(
      DMA1, LL_DMA_STREAM_2, LL_DMA_MDATAALIGN_BYTE);

  LL_DMA_DisableFifoMode(DMA1, LL_DMA_STREAM_2);

  LL_DMA_SetPeriphRequest(
      DMA1, LL_DMA_STREAM_3, LL_DMAMUX1_REQ_SPI1_TX);

  LL_DMA_SetDataTransferDirection(
      DMA1, LL_DMA_STREAM_3, LL_DMA_DIRECTION_MEMORY_TO_PERIPH);

  LL_DMA_SetStreamPriorityLevel(
      DMA1, LL_DMA_STREAM_3, LL_DMA_PRIORITY_HIGH);

  LL_DMA_SetMode(DMA1, LL_DMA_STREAM_3, LL_DMA_MODE_NORMAL);

  LL_DMA_SetPeriphIncMode(
      DMA1, LL_DMA_STREAM_3, LL_DMA_PERIPH_NOINCREMENT);

  LL_DMA_SetMemoryIncMode(
      DMA1, LL_DMA_STREAM_3, LL_DMA_MEMORY_INCREMENT);

  LL_DMA_SetPeriphSize(
      DMA1, LL_DMA_STREAM_3, LL_DMA_PDATAALIGN_BYTE);

  LL_DMA_SetMemorySize(
      DMA1, LL_DMA_STREAM_3, LL_DMA_MDATAALIGN_BYTE);

  LL_DMA_DisableFifoMode(DMA1, LL_DMA_STREAM_3);

  NVIC_SetPriority(
      SPI1_IRQn,
      NVIC_EncodePriority(NVIC_GetPriorityGrouping(), 0, 0));

  NVIC_EnableIRQ(SPI1_IRQn);

  SPI_InitStruct.TransferDirection = LL_SPI_FULL_DUPLEX;
  SPI_InitStruct.Mode = LL_SPI_MODE_MASTER;
  SPI_InitStruct.DataWidth = LL_SPI_DATAWIDTH_8BIT;
  SPI_InitStruct.ClockPolarity = LL_SPI_POLARITY_LOW;
  SPI_InitStruct.ClockPhase = LL_SPI_PHASE_1EDGE;
  SPI_InitStruct.NSS = LL_SPI_NSS_SOFT;
  SPI_InitStruct.BaudRate = LL_SPI_BAUDRATEPRESCALER_DIV2;
  SPI_InitStruct.BitOrder = LL_SPI_MSB_FIRST;
  SPI_InitStruct.CRCCalculation = LL_SPI_CRCCALCULATION_DISABLE;
  SPI_InitStruct.CRCPoly = 0x0;

  LL_SPI_Disable(SPI1);
  LL_SPI_Init(SPI1, &SPI_InitStruct);

  LL_SPI_SetStandard(SPI1, LL_SPI_PROTOCOL_MOTOROLA);
  LL_SPI_SetFIFOThreshold(SPI1, LL_SPI_FIFO_TH_01DATA);
  LL_SPI_DisableNSSPulseMgt(SPI1);

}

static void MX_SPI2_Init(void)
{

  LL_SPI_InitTypeDef SPI_InitStruct = {0};
  LL_GPIO_InitTypeDef GPIO_InitStruct = {0};

  LL_RCC_SetSPIClockSource(LL_RCC_SPI123_CLKSOURCE_PLL2P);

  LL_APB1_GRP1_EnableClock(LL_APB1_GRP1_PERIPH_SPI2);

  LL_AHB4_GRP1_EnableClock(LL_AHB4_GRP1_PERIPH_GPIOC);
  LL_AHB4_GRP1_EnableClock(LL_AHB4_GRP1_PERIPH_GPIOB);

  LL_SYSCFG_CloseAnalogSwitch(LL_SYSCFG_ANALOG_SWITCH_PC2);

  GPIO_InitStruct.Pin = LL_GPIO_PIN_1 | LL_GPIO_PIN_2;
  GPIO_InitStruct.Mode = LL_GPIO_MODE_ALTERNATE;
  GPIO_InitStruct.Speed = LL_GPIO_SPEED_FREQ_VERY_HIGH;
  GPIO_InitStruct.OutputType = LL_GPIO_OUTPUT_PUSHPULL;
  GPIO_InitStruct.Pull = LL_GPIO_PULL_NO;
  GPIO_InitStruct.Alternate = LL_GPIO_AF_5;

  LL_GPIO_Init(GPIOC, &GPIO_InitStruct);

  GPIO_InitStruct.Pin = LL_GPIO_PIN_10;
  GPIO_InitStruct.Mode = LL_GPIO_MODE_ALTERNATE;
  GPIO_InitStruct.Speed = LL_GPIO_SPEED_FREQ_VERY_HIGH;
  GPIO_InitStruct.OutputType = LL_GPIO_OUTPUT_PUSHPULL;
  GPIO_InitStruct.Pull = LL_GPIO_PULL_NO;
  GPIO_InitStruct.Alternate = LL_GPIO_AF_5;

  LL_GPIO_Init(GPIOB, &GPIO_InitStruct);

  LL_DMA_SetPeriphRequest(
      DMA1, LL_DMA_STREAM_4, LL_DMAMUX1_REQ_SPI2_RX);

  LL_DMA_SetDataTransferDirection(
      DMA1, LL_DMA_STREAM_4, LL_DMA_DIRECTION_PERIPH_TO_MEMORY);

  LL_DMA_SetStreamPriorityLevel(
      DMA1, LL_DMA_STREAM_4, LL_DMA_PRIORITY_VERYHIGH);

  LL_DMA_SetMode(DMA1, LL_DMA_STREAM_4, LL_DMA_MODE_NORMAL);

  LL_DMA_SetPeriphIncMode(
      DMA1, LL_DMA_STREAM_4, LL_DMA_PERIPH_NOINCREMENT);

  LL_DMA_SetMemoryIncMode(
      DMA1, LL_DMA_STREAM_4, LL_DMA_MEMORY_INCREMENT);

  LL_DMA_SetPeriphSize(
      DMA1, LL_DMA_STREAM_4, LL_DMA_PDATAALIGN_BYTE);

  LL_DMA_SetMemorySize(
      DMA1, LL_DMA_STREAM_4, LL_DMA_MDATAALIGN_BYTE);

  LL_DMA_DisableFifoMode(DMA1, LL_DMA_STREAM_4);

  LL_DMA_SetPeriphRequest(
      DMA1, LL_DMA_STREAM_5, LL_DMAMUX1_REQ_SPI2_TX);

  LL_DMA_SetDataTransferDirection(
      DMA1, LL_DMA_STREAM_5, LL_DMA_DIRECTION_MEMORY_TO_PERIPH);

  LL_DMA_SetStreamPriorityLevel(
      DMA1, LL_DMA_STREAM_5, LL_DMA_PRIORITY_HIGH);

  LL_DMA_SetMode(DMA1, LL_DMA_STREAM_5, LL_DMA_MODE_NORMAL);

  LL_DMA_SetPeriphIncMode(
      DMA1, LL_DMA_STREAM_5, LL_DMA_PERIPH_NOINCREMENT);

  LL_DMA_SetMemoryIncMode(
      DMA1, LL_DMA_STREAM_5, LL_DMA_MEMORY_INCREMENT);

  LL_DMA_SetPeriphSize(
      DMA1, LL_DMA_STREAM_5, LL_DMA_PDATAALIGN_BYTE);

  LL_DMA_SetMemorySize(
      DMA1, LL_DMA_STREAM_5, LL_DMA_MDATAALIGN_BYTE);

  LL_DMA_DisableFifoMode(DMA1, LL_DMA_STREAM_5);

  NVIC_SetPriority(
      SPI2_IRQn,
      NVIC_EncodePriority(NVIC_GetPriorityGrouping(), 0, 0));

  NVIC_EnableIRQ(SPI2_IRQn);

  SPI_InitStruct.TransferDirection = LL_SPI_FULL_DUPLEX;
  SPI_InitStruct.Mode = LL_SPI_MODE_MASTER;
  SPI_InitStruct.DataWidth = LL_SPI_DATAWIDTH_8BIT;
  SPI_InitStruct.ClockPolarity = LL_SPI_POLARITY_LOW;
  SPI_InitStruct.ClockPhase = LL_SPI_PHASE_1EDGE;
  SPI_InitStruct.NSS = LL_SPI_NSS_SOFT;
  SPI_InitStruct.BaudRate = LL_SPI_BAUDRATEPRESCALER_DIV2;
  SPI_InitStruct.BitOrder = LL_SPI_MSB_FIRST;
  SPI_InitStruct.CRCCalculation = LL_SPI_CRCCALCULATION_DISABLE;
  SPI_InitStruct.CRCPoly = 0x0;

  LL_SPI_Disable(SPI2);
  LL_SPI_Init(SPI2, &SPI_InitStruct);

  LL_SPI_SetStandard(SPI2, LL_SPI_PROTOCOL_MOTOROLA);
  LL_SPI_SetFIFOThreshold(SPI2, LL_SPI_FIFO_TH_01DATA);
  LL_SPI_DisableNSSPulseMgt(SPI2);

}

static void MX_SPI3_Init(void)
{

  LL_SPI_InitTypeDef SPI_InitStruct = {0};
  LL_GPIO_InitTypeDef GPIO_InitStruct = {0};

  LL_RCC_SetSPIClockSource(LL_RCC_SPI123_CLKSOURCE_PLL2P);

  LL_APB1_GRP1_EnableClock(LL_APB1_GRP1_PERIPH_SPI3);

  LL_AHB4_GRP1_EnableClock(LL_AHB4_GRP1_PERIPH_GPIOB);
  LL_AHB4_GRP1_EnableClock(LL_AHB4_GRP1_PERIPH_GPIOC);

  GPIO_InitStruct.Pin = LL_GPIO_PIN_2;
  GPIO_InitStruct.Mode = LL_GPIO_MODE_ALTERNATE;
  GPIO_InitStruct.Speed = LL_GPIO_SPEED_FREQ_VERY_HIGH;
  GPIO_InitStruct.OutputType = LL_GPIO_OUTPUT_PUSHPULL;
  GPIO_InitStruct.Pull = LL_GPIO_PULL_NO;
  GPIO_InitStruct.Alternate = LL_GPIO_AF_7;

  LL_GPIO_Init(GPIOB, &GPIO_InitStruct);

  GPIO_InitStruct.Pin = LL_GPIO_PIN_10 | LL_GPIO_PIN_11;
  GPIO_InitStruct.Mode = LL_GPIO_MODE_ALTERNATE;
  GPIO_InitStruct.Speed = LL_GPIO_SPEED_FREQ_VERY_HIGH;
  GPIO_InitStruct.OutputType = LL_GPIO_OUTPUT_PUSHPULL;
  GPIO_InitStruct.Pull = LL_GPIO_PULL_NO;
  GPIO_InitStruct.Alternate = LL_GPIO_AF_6;

  LL_GPIO_Init(GPIOC, &GPIO_InitStruct);

  LL_DMA_SetPeriphRequest(
      DMA1, LL_DMA_STREAM_6, LL_DMAMUX1_REQ_SPI3_RX);

  LL_DMA_SetDataTransferDirection(
      DMA1, LL_DMA_STREAM_6, LL_DMA_DIRECTION_PERIPH_TO_MEMORY);

  LL_DMA_SetStreamPriorityLevel(
      DMA1, LL_DMA_STREAM_6, LL_DMA_PRIORITY_VERYHIGH);

  LL_DMA_SetMode(DMA1, LL_DMA_STREAM_6, LL_DMA_MODE_NORMAL);

  LL_DMA_SetPeriphIncMode(
      DMA1, LL_DMA_STREAM_6, LL_DMA_PERIPH_NOINCREMENT);

  LL_DMA_SetMemoryIncMode(
      DMA1, LL_DMA_STREAM_6, LL_DMA_MEMORY_INCREMENT);

  LL_DMA_SetPeriphSize(
      DMA1, LL_DMA_STREAM_6, LL_DMA_PDATAALIGN_BYTE);

  LL_DMA_SetMemorySize(
      DMA1, LL_DMA_STREAM_6, LL_DMA_MDATAALIGN_BYTE);

  LL_DMA_DisableFifoMode(DMA1, LL_DMA_STREAM_6);

  LL_DMA_SetPeriphRequest(
      DMA1, LL_DMA_STREAM_7, LL_DMAMUX1_REQ_SPI3_TX);

  LL_DMA_SetDataTransferDirection(
      DMA1, LL_DMA_STREAM_7, LL_DMA_DIRECTION_MEMORY_TO_PERIPH);

  LL_DMA_SetStreamPriorityLevel(
      DMA1, LL_DMA_STREAM_7, LL_DMA_PRIORITY_HIGH);

  LL_DMA_SetMode(DMA1, LL_DMA_STREAM_7, LL_DMA_MODE_NORMAL);

  LL_DMA_SetPeriphIncMode(
      DMA1, LL_DMA_STREAM_7, LL_DMA_PERIPH_NOINCREMENT);

  LL_DMA_SetMemoryIncMode(
      DMA1, LL_DMA_STREAM_7, LL_DMA_MEMORY_INCREMENT);

  LL_DMA_SetPeriphSize(
      DMA1, LL_DMA_STREAM_7, LL_DMA_PDATAALIGN_BYTE);

  LL_DMA_SetMemorySize(
      DMA1, LL_DMA_STREAM_7, LL_DMA_MDATAALIGN_BYTE);

  LL_DMA_DisableFifoMode(DMA1, LL_DMA_STREAM_7);

  NVIC_SetPriority(
      SPI3_IRQn,
      NVIC_EncodePriority(NVIC_GetPriorityGrouping(), 0, 0));

  NVIC_EnableIRQ(SPI3_IRQn);

  SPI_InitStruct.TransferDirection = LL_SPI_FULL_DUPLEX;
  SPI_InitStruct.Mode = LL_SPI_MODE_MASTER;
  SPI_InitStruct.DataWidth = LL_SPI_DATAWIDTH_8BIT;
  SPI_InitStruct.ClockPolarity = LL_SPI_POLARITY_LOW;
  SPI_InitStruct.ClockPhase = LL_SPI_PHASE_1EDGE;
  SPI_InitStruct.NSS = LL_SPI_NSS_SOFT;
  SPI_InitStruct.BaudRate = LL_SPI_BAUDRATEPRESCALER_DIV2;
  SPI_InitStruct.BitOrder = LL_SPI_MSB_FIRST;
  SPI_InitStruct.CRCCalculation = LL_SPI_CRCCALCULATION_DISABLE;
  SPI_InitStruct.CRCPoly = 0x0;

  LL_SPI_Disable(SPI3);
  LL_SPI_Init(SPI3, &SPI_InitStruct);

  LL_SPI_SetStandard(SPI3, LL_SPI_PROTOCOL_MOTOROLA);
  LL_SPI_SetFIFOThreshold(SPI3, LL_SPI_FIFO_TH_01DATA);
  LL_SPI_DisableNSSPulseMgt(SPI3);

}

static void MX_SPI4_Init(void)
{

  LL_SPI_InitTypeDef SPI_InitStruct = {0};
  LL_GPIO_InitTypeDef GPIO_InitStruct = {0};

  LL_RCC_SetSPIClockSource(LL_RCC_SPI45_CLKSOURCE_PLL2Q);

  LL_APB2_GRP1_EnableClock(LL_APB2_GRP1_PERIPH_SPI4);
  LL_AHB4_GRP1_EnableClock(LL_AHB4_GRP1_PERIPH_GPIOE);

  GPIO_InitStruct.Pin =
      LL_GPIO_PIN_2 | LL_GPIO_PIN_5 | LL_GPIO_PIN_6;

  GPIO_InitStruct.Mode = LL_GPIO_MODE_ALTERNATE;
  GPIO_InitStruct.Speed = LL_GPIO_SPEED_FREQ_VERY_HIGH;
  GPIO_InitStruct.OutputType = LL_GPIO_OUTPUT_PUSHPULL;
  GPIO_InitStruct.Pull = LL_GPIO_PULL_NO;
  GPIO_InitStruct.Alternate = LL_GPIO_AF_5;

  LL_GPIO_Init(GPIOE, &GPIO_InitStruct);

  LL_DMA_SetPeriphRequest(
      DMA2, LL_DMA_STREAM_0, LL_DMAMUX1_REQ_SPI4_RX);

  LL_DMA_SetDataTransferDirection(
      DMA2, LL_DMA_STREAM_0, LL_DMA_DIRECTION_PERIPH_TO_MEMORY);

  LL_DMA_SetStreamPriorityLevel(
      DMA2, LL_DMA_STREAM_0, LL_DMA_PRIORITY_VERYHIGH);

  LL_DMA_SetMode(DMA2, LL_DMA_STREAM_0, LL_DMA_MODE_NORMAL);

  LL_DMA_SetPeriphIncMode(
      DMA2, LL_DMA_STREAM_0, LL_DMA_PERIPH_NOINCREMENT);

  LL_DMA_SetMemoryIncMode(
      DMA2, LL_DMA_STREAM_0, LL_DMA_MEMORY_INCREMENT);

  LL_DMA_SetPeriphSize(
      DMA2, LL_DMA_STREAM_0, LL_DMA_PDATAALIGN_BYTE);

  LL_DMA_SetMemorySize(
      DMA2, LL_DMA_STREAM_0, LL_DMA_MDATAALIGN_BYTE);

  LL_DMA_DisableFifoMode(DMA2, LL_DMA_STREAM_0);

  LL_DMA_SetPeriphRequest(
      DMA2, LL_DMA_STREAM_1, LL_DMAMUX1_REQ_SPI4_TX);

  LL_DMA_SetDataTransferDirection(
      DMA2, LL_DMA_STREAM_1, LL_DMA_DIRECTION_MEMORY_TO_PERIPH);

  LL_DMA_SetStreamPriorityLevel(
      DMA2, LL_DMA_STREAM_1, LL_DMA_PRIORITY_HIGH);

  LL_DMA_SetMode(DMA2, LL_DMA_STREAM_1, LL_DMA_MODE_NORMAL);

  LL_DMA_SetPeriphIncMode(
      DMA2, LL_DMA_STREAM_1, LL_DMA_PERIPH_NOINCREMENT);

  LL_DMA_SetMemoryIncMode(
      DMA2, LL_DMA_STREAM_1, LL_DMA_MEMORY_INCREMENT);

  LL_DMA_SetPeriphSize(
      DMA2, LL_DMA_STREAM_1, LL_DMA_PDATAALIGN_BYTE);

  LL_DMA_SetMemorySize(
      DMA2, LL_DMA_STREAM_1, LL_DMA_MDATAALIGN_BYTE);

  LL_DMA_DisableFifoMode(DMA2, LL_DMA_STREAM_1);

  NVIC_SetPriority(
      SPI4_IRQn,
      NVIC_EncodePriority(NVIC_GetPriorityGrouping(), 0, 0));

  NVIC_EnableIRQ(SPI4_IRQn);

  LL_SPI_Disable(SPI4);

  SPI_InitStruct.TransferDirection = LL_SPI_FULL_DUPLEX;
  SPI_InitStruct.Mode = LL_SPI_MODE_MASTER;
  SPI_InitStruct.DataWidth = LL_SPI_DATAWIDTH_8BIT;
  SPI_InitStruct.ClockPolarity = LL_SPI_POLARITY_LOW;
  SPI_InitStruct.ClockPhase = LL_SPI_PHASE_1EDGE;
  SPI_InitStruct.NSS = LL_SPI_NSS_SOFT;
  SPI_InitStruct.BaudRate = LL_SPI_BAUDRATEPRESCALER_DIV2;
  SPI_InitStruct.BitOrder = LL_SPI_MSB_FIRST;
  SPI_InitStruct.CRCCalculation = LL_SPI_CRCCALCULATION_DISABLE;
  SPI_InitStruct.CRCPoly = 0x0;

  LL_SPI_Init(SPI4, &SPI_InitStruct);

  LL_SPI_SetStandard(SPI4, LL_SPI_PROTOCOL_MOTOROLA);
  LL_SPI_SetFIFOThreshold(SPI4, LL_SPI_FIFO_TH_01DATA);
  LL_SPI_DisableNSSPulseMgt(SPI4);

}

static void MX_SPI5_Init(void)
{

  LL_SPI_InitTypeDef SPI_InitStruct = {0};
  LL_GPIO_InitTypeDef GPIO_InitStruct = {0};

  LL_RCC_SetSPIClockSource(LL_RCC_SPI45_CLKSOURCE_PLL2Q);

  LL_APB2_GRP1_EnableClock(LL_APB2_GRP1_PERIPH_SPI5);
  LL_AHB4_GRP1_EnableClock(LL_AHB4_GRP1_PERIPH_GPIOF);

  GPIO_InitStruct.Pin =
      LL_GPIO_PIN_7 | LL_GPIO_PIN_8 | LL_GPIO_PIN_9;

  GPIO_InitStruct.Mode = LL_GPIO_MODE_ALTERNATE;
  GPIO_InitStruct.Speed = LL_GPIO_SPEED_FREQ_VERY_HIGH;
  GPIO_InitStruct.OutputType = LL_GPIO_OUTPUT_PUSHPULL;
  GPIO_InitStruct.Pull = LL_GPIO_PULL_NO;
  GPIO_InitStruct.Alternate = LL_GPIO_AF_5;

  LL_GPIO_Init(GPIOF, &GPIO_InitStruct);

  LL_DMA_SetPeriphRequest(
      DMA2, LL_DMA_STREAM_2, LL_DMAMUX1_REQ_SPI5_RX);

  LL_DMA_SetDataTransferDirection(
      DMA2, LL_DMA_STREAM_2, LL_DMA_DIRECTION_PERIPH_TO_MEMORY);

  LL_DMA_SetStreamPriorityLevel(
      DMA2, LL_DMA_STREAM_2, LL_DMA_PRIORITY_VERYHIGH);

  LL_DMA_SetMode(DMA2, LL_DMA_STREAM_2, LL_DMA_MODE_NORMAL);

  LL_DMA_SetPeriphIncMode(
      DMA2, LL_DMA_STREAM_2, LL_DMA_PERIPH_NOINCREMENT);

  LL_DMA_SetMemoryIncMode(
      DMA2, LL_DMA_STREAM_2, LL_DMA_MEMORY_INCREMENT);

  LL_DMA_SetPeriphSize(
      DMA2, LL_DMA_STREAM_2, LL_DMA_PDATAALIGN_BYTE);

  LL_DMA_SetMemorySize(
      DMA2, LL_DMA_STREAM_2, LL_DMA_MDATAALIGN_BYTE);

  LL_DMA_DisableFifoMode(DMA2, LL_DMA_STREAM_2);

  LL_DMA_SetPeriphRequest(
      DMA2, LL_DMA_STREAM_3, LL_DMAMUX1_REQ_SPI5_TX);

  LL_DMA_SetDataTransferDirection(
      DMA2, LL_DMA_STREAM_3, LL_DMA_DIRECTION_MEMORY_TO_PERIPH);

  LL_DMA_SetStreamPriorityLevel(
      DMA2, LL_DMA_STREAM_3, LL_DMA_PRIORITY_HIGH);

  LL_DMA_SetMode(DMA2, LL_DMA_STREAM_3, LL_DMA_MODE_NORMAL);

  LL_DMA_SetPeriphIncMode(
      DMA2, LL_DMA_STREAM_3, LL_DMA_PERIPH_NOINCREMENT);

  LL_DMA_SetMemoryIncMode(
      DMA2, LL_DMA_STREAM_3, LL_DMA_MEMORY_INCREMENT);

  LL_DMA_SetPeriphSize(
      DMA2, LL_DMA_STREAM_3, LL_DMA_PDATAALIGN_BYTE);

  LL_DMA_SetMemorySize(
      DMA2, LL_DMA_STREAM_3, LL_DMA_MDATAALIGN_BYTE);

  LL_DMA_DisableFifoMode(DMA2, LL_DMA_STREAM_3);

  NVIC_SetPriority(
      SPI5_IRQn,
      NVIC_EncodePriority(NVIC_GetPriorityGrouping(), 0, 0));

  NVIC_EnableIRQ(SPI5_IRQn);

  SPI_InitStruct.TransferDirection = LL_SPI_FULL_DUPLEX;
  SPI_InitStruct.Mode = LL_SPI_MODE_MASTER;
  SPI_InitStruct.DataWidth = LL_SPI_DATAWIDTH_8BIT;
  SPI_InitStruct.ClockPolarity = LL_SPI_POLARITY_LOW;
  SPI_InitStruct.ClockPhase = LL_SPI_PHASE_1EDGE;
  SPI_InitStruct.NSS = LL_SPI_NSS_SOFT;
  SPI_InitStruct.BaudRate = LL_SPI_BAUDRATEPRESCALER_DIV2;
  SPI_InitStruct.BitOrder = LL_SPI_MSB_FIRST;
  SPI_InitStruct.CRCCalculation = LL_SPI_CRCCALCULATION_DISABLE;
  SPI_InitStruct.CRCPoly = 0x0;

  LL_SPI_Disable(SPI5);
  LL_SPI_Init(SPI5, &SPI_InitStruct);

  LL_SPI_SetStandard(SPI5, LL_SPI_PROTOCOL_MOTOROLA);
  LL_SPI_SetFIFOThreshold(SPI5, LL_SPI_FIFO_TH_01DATA);
  LL_SPI_DisableNSSPulseMgt(SPI5);

}

static void MX_SPI6_Init(void)
{

  LL_SPI_InitTypeDef SPI_InitStruct = {0};
  LL_GPIO_InitTypeDef GPIO_InitStruct = {0};

  LL_RCC_SetSPIClockSource(LL_RCC_SPI6_CLKSOURCE_PLL2Q);

  LL_APB4_GRP1_EnableClock(LL_APB4_GRP1_PERIPH_SPI6);

  LL_AHB4_GRP1_EnableClock(LL_AHB4_GRP1_PERIPH_GPIOC);
  LL_AHB4_GRP1_EnableClock(LL_AHB4_GRP1_PERIPH_GPIOG);

  GPIO_InitStruct.Pin = LL_GPIO_PIN_12;
  GPIO_InitStruct.Mode = LL_GPIO_MODE_ALTERNATE;
  GPIO_InitStruct.Speed = LL_GPIO_SPEED_FREQ_VERY_HIGH;
  GPIO_InitStruct.OutputType = LL_GPIO_OUTPUT_PUSHPULL;
  GPIO_InitStruct.Pull = LL_GPIO_PULL_NO;
  GPIO_InitStruct.Alternate = LL_GPIO_AF_5;

  LL_GPIO_Init(GPIOC, &GPIO_InitStruct);

  GPIO_InitStruct.Pin = LL_GPIO_PIN_12 | LL_GPIO_PIN_14;
  GPIO_InitStruct.Mode = LL_GPIO_MODE_ALTERNATE;
  GPIO_InitStruct.Speed = LL_GPIO_SPEED_FREQ_VERY_HIGH;
  GPIO_InitStruct.OutputType = LL_GPIO_OUTPUT_PUSHPULL;
  GPIO_InitStruct.Pull = LL_GPIO_PULL_NO;
  GPIO_InitStruct.Alternate = LL_GPIO_AF_5;

  LL_GPIO_Init(GPIOG, &GPIO_InitStruct);

  LL_BDMA_SetPeriphRequest(
      BDMA, LL_BDMA_CHANNEL_0, LL_DMAMUX2_REQ_SPI6_RX);

  LL_BDMA_SetDataTransferDirection(
      BDMA, LL_BDMA_CHANNEL_0, LL_BDMA_DIRECTION_PERIPH_TO_MEMORY);

  LL_BDMA_SetChannelPriorityLevel(
      BDMA, LL_BDMA_CHANNEL_0, LL_BDMA_PRIORITY_VERYHIGH);

  LL_BDMA_SetMode(BDMA, LL_BDMA_CHANNEL_0, LL_BDMA_MODE_NORMAL);

  LL_BDMA_SetPeriphIncMode(
      BDMA, LL_BDMA_CHANNEL_0, LL_BDMA_PERIPH_NOINCREMENT);

  LL_BDMA_SetMemoryIncMode(
      BDMA, LL_BDMA_CHANNEL_0, LL_BDMA_MEMORY_INCREMENT);

  LL_BDMA_SetPeriphSize(
      BDMA, LL_BDMA_CHANNEL_0, LL_BDMA_PDATAALIGN_BYTE);

  LL_BDMA_SetMemorySize(
      BDMA, LL_BDMA_CHANNEL_0, LL_BDMA_MDATAALIGN_BYTE);

  LL_BDMA_SetPeriphRequest(
      BDMA, LL_BDMA_CHANNEL_1, LL_DMAMUX2_REQ_SPI6_TX);

  LL_BDMA_SetDataTransferDirection(
      BDMA, LL_BDMA_CHANNEL_1, LL_BDMA_DIRECTION_MEMORY_TO_PERIPH);

  LL_BDMA_SetChannelPriorityLevel(
      BDMA, LL_BDMA_CHANNEL_1, LL_BDMA_PRIORITY_HIGH);

  LL_BDMA_SetMode(BDMA, LL_BDMA_CHANNEL_1, LL_BDMA_MODE_NORMAL);

  LL_BDMA_SetPeriphIncMode(
      BDMA, LL_BDMA_CHANNEL_1, LL_BDMA_PERIPH_NOINCREMENT);

  LL_BDMA_SetMemoryIncMode(
      BDMA, LL_BDMA_CHANNEL_1, LL_BDMA_MEMORY_INCREMENT);

  LL_BDMA_SetPeriphSize(
      BDMA, LL_BDMA_CHANNEL_1, LL_BDMA_PDATAALIGN_BYTE);

  LL_BDMA_SetMemorySize(
      BDMA, LL_BDMA_CHANNEL_1, LL_BDMA_MDATAALIGN_BYTE);

  NVIC_SetPriority(
      SPI6_IRQn,
      NVIC_EncodePriority(NVIC_GetPriorityGrouping(), 0, 0));

  NVIC_EnableIRQ(SPI6_IRQn);

  SPI_InitStruct.TransferDirection = LL_SPI_FULL_DUPLEX;
  SPI_InitStruct.Mode = LL_SPI_MODE_MASTER;
  SPI_InitStruct.DataWidth = LL_SPI_DATAWIDTH_8BIT;
  SPI_InitStruct.ClockPolarity = LL_SPI_POLARITY_LOW;
  SPI_InitStruct.ClockPhase = LL_SPI_PHASE_1EDGE;
  SPI_InitStruct.NSS = LL_SPI_NSS_SOFT;
  SPI_InitStruct.BaudRate = LL_SPI_BAUDRATEPRESCALER_DIV2;
  SPI_InitStruct.BitOrder = LL_SPI_MSB_FIRST;
  SPI_InitStruct.CRCCalculation = LL_SPI_CRCCALCULATION_DISABLE;
  SPI_InitStruct.CRCPoly = 0x0;

  LL_SPI_Disable(SPI6);
  LL_SPI_Init(SPI6, &SPI_InitStruct);

  LL_SPI_SetStandard(SPI6, LL_SPI_PROTOCOL_MOTOROLA);
  LL_SPI_SetFIFOThreshold(SPI6, LL_SPI_FIFO_TH_01DATA);
  LL_SPI_DisableNSSPulseMgt(SPI6);

}

static void MX_TIM6_Init(void)
{

  LL_TIM_InitTypeDef TIM_InitStruct = {0};

  LL_APB1_GRP1_EnableClock(LL_APB1_GRP1_PERIPH_TIM6);

  NVIC_SetPriority(
      TIM6_DAC_IRQn,
      NVIC_EncodePriority(NVIC_GetPriorityGrouping(), 0, 0));

  NVIC_EnableIRQ(TIM6_DAC_IRQn);

  /*
   * TIM6CLK = 275 MHz.
   * 275 MHz / (274 + 1) = 1 MHz.
   * 1 MHz / (2499 + 1) = 400 Hz.
   */
  TIM_InitStruct.Prescaler = 274U;
  TIM_InitStruct.CounterMode = LL_TIM_COUNTERMODE_UP;
  TIM_InitStruct.Autoreload = 2499U;

  LL_TIM_Init(TIM6, &TIM_InitStruct);

  LL_TIM_DisableARRPreload(TIM6);
  LL_TIM_SetTriggerOutput(TIM6, LL_TIM_TRGO_RESET);
  LL_TIM_DisableMasterSlaveMode(TIM6);

}

static void MX_TIM7_Init(void)
{

  LL_TIM_InitTypeDef TIM_InitStruct = {0};

  LL_APB1_GRP1_EnableClock(LL_APB1_GRP1_PERIPH_TIM7);

  /*
   * TIM7CLK = 275 MHz.
   * 275 MHz / (274 + 1) / (999 + 1) = 1 kHz.
   */
  TIM_InitStruct.Prescaler = 274U;
  TIM_InitStruct.CounterMode = LL_TIM_COUNTERMODE_UP;
  TIM_InitStruct.Autoreload = 999U;

  LL_TIM_Init(TIM7, &TIM_InitStruct);

  LL_TIM_DisableARRPreload(TIM7);
  LL_TIM_SetTriggerOutput(TIM7, LL_TIM_TRGO_RESET);
  LL_TIM_DisableMasterSlaveMode(TIM7);

  /* USER CODE BEGIN TIM7_Init 2 */

  NVIC_SetPriority(
      TIM7_IRQn,
      NVIC_EncodePriority(NVIC_GetPriorityGrouping(), 3U, 0U));

  NVIC_EnableIRQ(TIM7_IRQn);

  /* USER CODE END TIM7_Init 2 */
}

static void MX_USART1_UART_Init(void)
{

  LL_USART_InitTypeDef USART_InitStruct = {0};
  LL_GPIO_InitTypeDef GPIO_InitStruct = {0};

  LL_RCC_SetUSARTClockSource(LL_RCC_USART16_CLKSOURCE_PCLK2);

  LL_APB2_GRP1_EnableClock(LL_APB2_GRP1_PERIPH_USART1);
  LL_AHB4_GRP1_EnableClock(LL_AHB4_GRP1_PERIPH_GPIOB);

  GPIO_InitStruct.Pin = LL_GPIO_PIN_14 | LL_GPIO_PIN_15;
  GPIO_InitStruct.Mode = LL_GPIO_MODE_ALTERNATE;
  GPIO_InitStruct.Speed = LL_GPIO_SPEED_FREQ_VERY_HIGH;
  GPIO_InitStruct.OutputType = LL_GPIO_OUTPUT_PUSHPULL;
  GPIO_InitStruct.Pull = LL_GPIO_PULL_NO;
  GPIO_InitStruct.Alternate = LL_GPIO_AF_4;

  LL_GPIO_Init(GPIOB, &GPIO_InitStruct);

  LL_DMA_SetPeriphRequest(
      DMA1, LL_DMA_STREAM_0, LL_DMAMUX1_REQ_USART1_RX);

  LL_DMA_SetDataTransferDirection(
      DMA1, LL_DMA_STREAM_0, LL_DMA_DIRECTION_PERIPH_TO_MEMORY);

  LL_DMA_SetStreamPriorityLevel(
      DMA1, LL_DMA_STREAM_0, LL_DMA_PRIORITY_HIGH);

  LL_DMA_SetMode(DMA1, LL_DMA_STREAM_0, LL_DMA_MODE_NORMAL);

  LL_DMA_SetPeriphIncMode(
      DMA1, LL_DMA_STREAM_0, LL_DMA_PERIPH_NOINCREMENT);

  LL_DMA_SetMemoryIncMode(
      DMA1, LL_DMA_STREAM_0, LL_DMA_MEMORY_INCREMENT);

  LL_DMA_SetPeriphSize(
      DMA1, LL_DMA_STREAM_0, LL_DMA_PDATAALIGN_BYTE);

  LL_DMA_SetMemorySize(
      DMA1, LL_DMA_STREAM_0, LL_DMA_MDATAALIGN_BYTE);

  LL_DMA_DisableFifoMode(DMA1, LL_DMA_STREAM_0);

  LL_DMA_SetPeriphRequest(
      DMA1, LL_DMA_STREAM_1, LL_DMAMUX1_REQ_USART1_TX);

  LL_DMA_SetDataTransferDirection(
      DMA1, LL_DMA_STREAM_1, LL_DMA_DIRECTION_MEMORY_TO_PERIPH);

  LL_DMA_SetStreamPriorityLevel(
      DMA1, LL_DMA_STREAM_1, LL_DMA_PRIORITY_MEDIUM);

  LL_DMA_SetMode(DMA1, LL_DMA_STREAM_1, LL_DMA_MODE_NORMAL);

  LL_DMA_SetPeriphIncMode(
      DMA1, LL_DMA_STREAM_1, LL_DMA_PERIPH_NOINCREMENT);

  LL_DMA_SetMemoryIncMode(
      DMA1, LL_DMA_STREAM_1, LL_DMA_MEMORY_INCREMENT);

  LL_DMA_SetPeriphSize(
      DMA1, LL_DMA_STREAM_1, LL_DMA_PDATAALIGN_BYTE);

  LL_DMA_SetMemorySize(
      DMA1, LL_DMA_STREAM_1, LL_DMA_MDATAALIGN_BYTE);

  LL_DMA_DisableFifoMode(DMA1, LL_DMA_STREAM_1);

  USART_InitStruct.PrescalerValue = LL_USART_PRESCALER_DIV1;
  USART_InitStruct.BaudRate = 6000000;
  USART_InitStruct.DataWidth = LL_USART_DATAWIDTH_8B;
  USART_InitStruct.StopBits = LL_USART_STOPBITS_1;
  USART_InitStruct.Parity = LL_USART_PARITY_NONE;
  USART_InitStruct.TransferDirection = LL_USART_DIRECTION_TX_RX;
  USART_InitStruct.HardwareFlowControl = LL_USART_HWCONTROL_NONE;
  USART_InitStruct.OverSampling = LL_USART_OVERSAMPLING_8;

  LL_USART_Init(USART1, &USART_InitStruct);

  LL_USART_SetTXFIFOThreshold(USART1, LL_USART_FIFOTHRESHOLD_1_8);
  LL_USART_SetRXFIFOThreshold(USART1, LL_USART_FIFOTHRESHOLD_1_8);

  LL_USART_DisableFIFO(USART1);
  LL_USART_ConfigAsyncMode(USART1);

  LL_USART_Enable(USART1);

  while ((!LL_USART_IsActiveFlag_TEACK(USART1)) ||
         (!LL_USART_IsActiveFlag_REACK(USART1)))
  {
  }

}

static void MX_BDMA_Init(void)
{
  LL_AHB4_GRP1_EnableClock(LL_AHB4_GRP1_PERIPH_BDMA);

  NVIC_SetPriority(
      BDMA_Channel0_IRQn,
      NVIC_EncodePriority(NVIC_GetPriorityGrouping(), 0, 0));

  NVIC_EnableIRQ(BDMA_Channel0_IRQn);

  NVIC_SetPriority(
      BDMA_Channel1_IRQn,
      NVIC_EncodePriority(NVIC_GetPriorityGrouping(), 0, 0));

  NVIC_EnableIRQ(BDMA_Channel1_IRQn);
}

static void MX_DMA_Init(void)
{
  LL_AHB1_GRP1_EnableClock(LL_AHB1_GRP1_PERIPH_DMA1);
  LL_AHB1_GRP1_EnableClock(LL_AHB1_GRP1_PERIPH_DMA2);

  NVIC_SetPriority(
      DMA1_Stream0_IRQn,
      NVIC_EncodePriority(NVIC_GetPriorityGrouping(), 0, 0));
  NVIC_EnableIRQ(DMA1_Stream0_IRQn);

  NVIC_SetPriority(
      DMA1_Stream1_IRQn,
      NVIC_EncodePriority(NVIC_GetPriorityGrouping(), 0, 0));
  NVIC_EnableIRQ(DMA1_Stream1_IRQn);

  NVIC_SetPriority(
      DMA1_Stream2_IRQn,
      NVIC_EncodePriority(NVIC_GetPriorityGrouping(), 0, 0));
  NVIC_EnableIRQ(DMA1_Stream2_IRQn);

  NVIC_SetPriority(
      DMA1_Stream3_IRQn,
      NVIC_EncodePriority(NVIC_GetPriorityGrouping(), 0, 0));
  NVIC_EnableIRQ(DMA1_Stream3_IRQn);

  NVIC_SetPriority(
      DMA1_Stream4_IRQn,
      NVIC_EncodePriority(NVIC_GetPriorityGrouping(), 0, 0));
  NVIC_EnableIRQ(DMA1_Stream4_IRQn);

  NVIC_SetPriority(
      DMA1_Stream5_IRQn,
      NVIC_EncodePriority(NVIC_GetPriorityGrouping(), 0, 0));
  NVIC_EnableIRQ(DMA1_Stream5_IRQn);

  NVIC_SetPriority(
      DMA1_Stream6_IRQn,
      NVIC_EncodePriority(NVIC_GetPriorityGrouping(), 0, 0));
  NVIC_EnableIRQ(DMA1_Stream6_IRQn);

  NVIC_SetPriority(
      DMA1_Stream7_IRQn,
      NVIC_EncodePriority(NVIC_GetPriorityGrouping(), 0, 0));
  NVIC_EnableIRQ(DMA1_Stream7_IRQn);

  NVIC_SetPriority(
      DMA2_Stream0_IRQn,
      NVIC_EncodePriority(NVIC_GetPriorityGrouping(), 0, 0));
  NVIC_EnableIRQ(DMA2_Stream0_IRQn);

  NVIC_SetPriority(
      DMA2_Stream1_IRQn,
      NVIC_EncodePriority(NVIC_GetPriorityGrouping(), 0, 0));
  NVIC_EnableIRQ(DMA2_Stream1_IRQn);

  NVIC_SetPriority(
      DMA2_Stream2_IRQn,
      NVIC_EncodePriority(NVIC_GetPriorityGrouping(), 0, 0));
  NVIC_EnableIRQ(DMA2_Stream2_IRQn);

  NVIC_SetPriority(
      DMA2_Stream3_IRQn,
      NVIC_EncodePriority(NVIC_GetPriorityGrouping(), 0, 0));
  NVIC_EnableIRQ(DMA2_Stream3_IRQn);
}

static void MX_GPIO_Init(void)
{
  LL_GPIO_InitTypeDef GPIO_InitStruct = {0};

  LL_AHB4_GRP1_EnableClock(LL_AHB4_GRP1_PERIPH_GPIOA);
  LL_AHB4_GRP1_EnableClock(LL_AHB4_GRP1_PERIPH_GPIOB);
  LL_AHB4_GRP1_EnableClock(LL_AHB4_GRP1_PERIPH_GPIOC);
  LL_AHB4_GRP1_EnableClock(LL_AHB4_GRP1_PERIPH_GPIOD);
  LL_AHB4_GRP1_EnableClock(LL_AHB4_GRP1_PERIPH_GPIOE);
  LL_AHB4_GRP1_EnableClock(LL_AHB4_GRP1_PERIPH_GPIOF);
  LL_AHB4_GRP1_EnableClock(LL_AHB4_GRP1_PERIPH_GPIOG);
  LL_AHB4_GRP1_EnableClock(LL_AHB4_GRP1_PERIPH_GPIOH);

  LL_GPIO_SetOutputPin(
      GPIOA,
      LL_GPIO_PIN_8 | LL_GPIO_PIN_9 | LL_GPIO_PIN_10);

  LL_GPIO_SetOutputPin(
      GPIOB,
      LL_GPIO_PIN_0 | LL_GPIO_PIN_1 |
      LL_GPIO_PIN_3 | LL_GPIO_PIN_4 |
      LL_GPIO_PIN_8 | LL_GPIO_PIN_12 | LL_GPIO_PIN_13);

  LL_GPIO_SetOutputPin(
      GPIOC,
      LL_GPIO_PIN_4 | LL_GPIO_PIN_5 | LL_GPIO_PIN_9);

  LL_GPIO_SetOutputPin(
      GPIOD,
      LL_GPIO_PIN_0 | LL_GPIO_PIN_1 |
      LL_GPIO_PIN_2 | LL_GPIO_PIN_3 |
      LL_GPIO_PIN_4 | LL_GPIO_PIN_5 |
      LL_GPIO_PIN_6 | LL_GPIO_PIN_7);

  LL_GPIO_SetOutputPin(
      GPIOE,
      LL_GPIO_PIN_0 | LL_GPIO_PIN_7 |
      LL_GPIO_PIN_8 | LL_GPIO_PIN_9 |
      LL_GPIO_PIN_10 | LL_GPIO_PIN_11 |
      LL_GPIO_PIN_14 | LL_GPIO_PIN_15);

  LL_GPIO_SetOutputPin(
      GPIOF,
      LL_GPIO_PIN_13 | LL_GPIO_PIN_14 | LL_GPIO_PIN_15);

  LL_GPIO_SetOutputPin(
      GPIOG,
      LL_GPIO_PIN_0 | LL_GPIO_PIN_1 |
      LL_GPIO_PIN_5 | LL_GPIO_PIN_9 | LL_GPIO_PIN_15);

  GPIO_InitStruct.Pin = LL_GPIO_PIN_3;
  GPIO_InitStruct.Mode = LL_GPIO_MODE_ANALOG;
  GPIO_InitStruct.Pull = LL_GPIO_PULL_NO;

  LL_GPIO_Init(GPIOE, &GPIO_InitStruct);

  GPIO_InitStruct.Pin =
      LL_GPIO_PIN_8 | LL_GPIO_PIN_9 | LL_GPIO_PIN_10;

  GPIO_InitStruct.Mode = LL_GPIO_MODE_OUTPUT;
  GPIO_InitStruct.Speed = LL_GPIO_SPEED_FREQ_VERY_HIGH;
  GPIO_InitStruct.OutputType = LL_GPIO_OUTPUT_PUSHPULL;
  GPIO_InitStruct.Pull = LL_GPIO_PULL_NO;

  LL_GPIO_Init(GPIOA, &GPIO_InitStruct);

  GPIO_InitStruct.Pin =
      LL_GPIO_PIN_0 | LL_GPIO_PIN_1 |
      LL_GPIO_PIN_3 | LL_GPIO_PIN_4 |
      LL_GPIO_PIN_8 | LL_GPIO_PIN_12 | LL_GPIO_PIN_13;

  GPIO_InitStruct.Mode = LL_GPIO_MODE_OUTPUT;
  GPIO_InitStruct.Speed = LL_GPIO_SPEED_FREQ_VERY_HIGH;
  GPIO_InitStruct.OutputType = LL_GPIO_OUTPUT_PUSHPULL;
  GPIO_InitStruct.Pull = LL_GPIO_PULL_NO;

  LL_GPIO_Init(GPIOB, &GPIO_InitStruct);

  GPIO_InitStruct.Pin =
      LL_GPIO_PIN_4 | LL_GPIO_PIN_5 | LL_GPIO_PIN_9;

  GPIO_InitStruct.Mode = LL_GPIO_MODE_OUTPUT;
  GPIO_InitStruct.Speed = LL_GPIO_SPEED_FREQ_VERY_HIGH;
  GPIO_InitStruct.OutputType = LL_GPIO_OUTPUT_PUSHPULL;
  GPIO_InitStruct.Pull = LL_GPIO_PULL_NO;

  LL_GPIO_Init(GPIOC, &GPIO_InitStruct);

  GPIO_InitStruct.Pin =
      LL_GPIO_PIN_0 | LL_GPIO_PIN_1 |
      LL_GPIO_PIN_2 | LL_GPIO_PIN_3 |
      LL_GPIO_PIN_4 | LL_GPIO_PIN_5 |
      LL_GPIO_PIN_6 | LL_GPIO_PIN_7;

  GPIO_InitStruct.Mode = LL_GPIO_MODE_OUTPUT;
  GPIO_InitStruct.Speed = LL_GPIO_SPEED_FREQ_HIGH;
  GPIO_InitStruct.OutputType = LL_GPIO_OUTPUT_PUSHPULL;
  GPIO_InitStruct.Pull = LL_GPIO_PULL_NO;

  LL_GPIO_Init(GPIOD, &GPIO_InitStruct);

  GPIO_InitStruct.Pin =
      LL_GPIO_PIN_0 | LL_GPIO_PIN_7 |
      LL_GPIO_PIN_8 | LL_GPIO_PIN_9 |
      LL_GPIO_PIN_10 | LL_GPIO_PIN_11 |
      LL_GPIO_PIN_14 | LL_GPIO_PIN_15;

  GPIO_InitStruct.Mode = LL_GPIO_MODE_OUTPUT;
  GPIO_InitStruct.Speed = LL_GPIO_SPEED_FREQ_VERY_HIGH;
  GPIO_InitStruct.OutputType = LL_GPIO_OUTPUT_PUSHPULL;
  GPIO_InitStruct.Pull = LL_GPIO_PULL_NO;

  LL_GPIO_Init(GPIOE, &GPIO_InitStruct);

  GPIO_InitStruct.Pin =
      LL_GPIO_PIN_13 | LL_GPIO_PIN_14 | LL_GPIO_PIN_15;

  GPIO_InitStruct.Mode = LL_GPIO_MODE_OUTPUT;
  GPIO_InitStruct.Speed = LL_GPIO_SPEED_FREQ_VERY_HIGH;
  GPIO_InitStruct.OutputType = LL_GPIO_OUTPUT_PUSHPULL;
  GPIO_InitStruct.Pull = LL_GPIO_PULL_NO;

  LL_GPIO_Init(GPIOF, &GPIO_InitStruct);

  LL_GPIO_SetOutputPin(GPIOG, LL_GPIO_PIN_5);

  GPIO_InitStruct.Pin =
      LL_GPIO_PIN_0 | LL_GPIO_PIN_1 |
      LL_GPIO_PIN_5 | LL_GPIO_PIN_9 | LL_GPIO_PIN_15;

  GPIO_InitStruct.Mode = LL_GPIO_MODE_OUTPUT;
  GPIO_InitStruct.Speed = LL_GPIO_SPEED_FREQ_VERY_HIGH;
  GPIO_InitStruct.OutputType = LL_GPIO_OUTPUT_PUSHPULL;
  GPIO_InitStruct.Pull = LL_GPIO_PULL_NO;

  LL_GPIO_Init(GPIOG, &GPIO_InitStruct);
}

void MPU_Config(void)
{
  LL_MPU_Disable();

  /* D2: SPI1...SPI5 DMA buffers. */
  LL_MPU_ConfigRegion(
      LL_MPU_REGION_NUMBER0,
      0x00U,
      0x30000000U,
      LL_MPU_REGION_SIZE_256KB |
      LL_MPU_REGION_PRIV_RW |
      LL_MPU_ACCESS_NOT_BUFFERABLE |
      LL_MPU_ACCESS_NOT_CACHEABLE |
      LL_MPU_ACCESS_SHAREABLE |
      LL_MPU_INSTRUCTION_ACCESS_DISABLE);

  LL_MPU_EnableRegion(LL_MPU_REGION_NUMBER0);

  /* D3/SRAM4: SPI6 BDMA buffers. */
  LL_MPU_ConfigRegion(
      LL_MPU_REGION_NUMBER1,
      0x00U,
      0x38000000U,
      LL_MPU_REGION_SIZE_32KB |
      LL_MPU_REGION_PRIV_RW |
      LL_MPU_ACCESS_NOT_BUFFERABLE |
      LL_MPU_ACCESS_NOT_CACHEABLE |
      LL_MPU_ACCESS_SHAREABLE |
      LL_MPU_INSTRUCTION_ACCESS_DISABLE);

  LL_MPU_EnableRegion(LL_MPU_REGION_NUMBER1);

  /*
   * AXI SRAM UART queue не покрывается новым MPU region.
   * Cache coherency обеспечивается UART_CleanTxDCache().
   */
  LL_MPU_Enable(LL_MPU_CTRL_PRIVILEGED_DEFAULT);
}

void Error_Handler(void)
{
  __disable_irq();
  while (1)
  {
  }
}

#ifdef USE_FULL_ASSERT

void assert_failed(uint8_t *file, uint32_t line)
{
  /* USER CODE BEGIN 6 */

  (void)file;
  (void)line;

  /* USER CODE END 6 */
}

#endif
